LIN_description_file;
LIN_protocol_version = "J2602_1_2.0";
LIN_language_version = "J2602_3_2.0";
LDF_file_revision = "14.23.01";
LIN_speed = 10.417 kbps;

Nodes {
  Commander: CEM, 5 ms, 0.1 ms, 34 bit, 30 %;
  Responders: LSM ;
}

Signals {
  InternalLightsRequest: 2, 0, CEM, LSM ;
  LeftIntLightsSwitch: 8, 0, LSM, CEM ;
  LSMerror: 1, 0, LSM, CEM ;
  IntTest: 2, 0, LSM, CEM ;
  Character: 8, 0, CEM, LSM ;
  Digit: 4, 0, CEM, LSM ;
  Load: 32, {0, 0, 0, 0}, LSM, CEM ;
  LSM_Reset: 1, 0, LSM, CEM ;
  CEM_Frm2_NewSignal: 8, 0, CEM ;
}

Diagnostic_signals {
  CommanderReqB0: 8, 0 ;
  CommanderReqB1: 8, 0 ;
  CommanderReqB2: 8, 0 ;
  CommanderReqB3: 8, 0 ;
  CommanderReqB4: 8, 0 ;
  CommanderReqB5: 8, 0 ;
  CommanderReqB6: 8, 0 ;
  CommanderReqB7: 8, 0 ;
  ResponderRespB0: 8, 0 ;
  ResponderRespB1: 8, 0 ;
  ResponderRespB2: 8, 0 ;
  ResponderRespB3: 8, 0 ;
  ResponderRespB4: 8, 0 ;
  ResponderRespB5: 8, 0 ;
  ResponderRespB6: 8, 0 ;
  ResponderRespB7: 8, 0 ;
}

Frames {
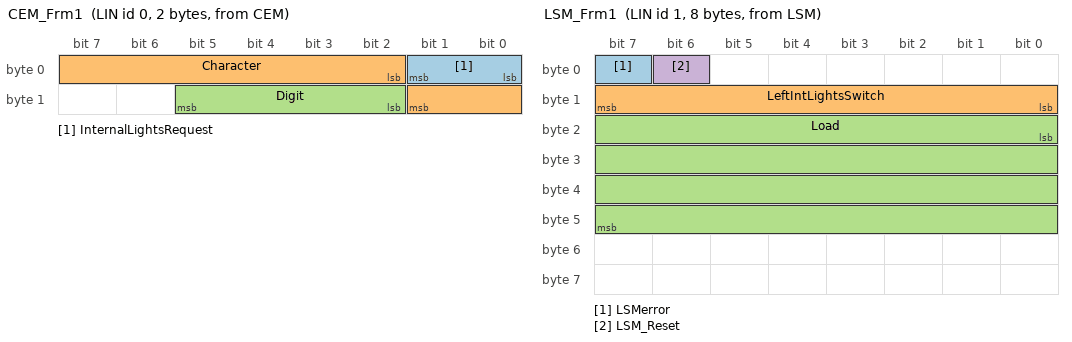
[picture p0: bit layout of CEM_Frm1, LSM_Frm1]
  CEM_Frm1: 0, CEM, 2 {
    InternalLightsRequest, 0 ;
    Character, 2 ;
    Digit, 10 ;
  }
  LSM_Frm1: 1, LSM, 8 {
    LSMerror, 7 ;
    LeftIntLightsSwitch, 8 ;
    Load, 16 ;
    LSM_Reset, 6 ;
  }
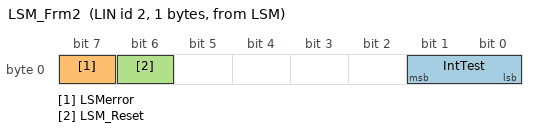
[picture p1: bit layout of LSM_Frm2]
  LSM_Frm2: 2, LSM, 1 {
    IntTest, 0 ;
    LSMerror, 7 ;
    LSM_Reset, 6 ;
  }
}

Diagnostic_frames {
  CommanderReq: 0x3c {
    CommanderReqB0, 0 ;
    CommanderReqB1, 8 ;
    CommanderReqB2, 16 ;
    CommanderReqB3, 24 ;
    CommanderReqB4, 32 ;
    CommanderReqB5, 40 ;
    CommanderReqB6, 48 ;
    CommanderReqB7, 56 ;
  }
  ResponderResp: 0x3d {
    ResponderRespB0, 0 ;
    ResponderRespB1, 8 ;
    ResponderRespB2, 16 ;
    ResponderRespB3, 24 ;
    ResponderRespB4, 32 ;
    ResponderRespB5, 40 ;
    ResponderRespB6, 48 ;
    ResponderRespB7, 56 ;
  }
}

Node_attributes {
  LSM{
    LIN_protocol = "J2602_1_2.0" ;
    configured_NAD = 0x60 ;
    initial_NAD = 0x60 ;
    product_id = 0x4A4F, 0x4841, 255 ;
    response_error = LSMerror ;
    fault_state_signals = IntTest ;
    P2_min = 10 ms ;
    ST_min = 0 ms ;
    N_As_timeout = 0 ms ;
    N_Cr_timeout = 0 ms ;
    response_tolerance = 30 % ;
    wakeup_time = 60 ms;
    poweron_time = 90 ms;
    configurable_frames {
      CEM_Frm1 ;
      LSM_Frm1 ;
      LSM_Frm2 ;
    }
  }
}

Schedule_tables {
 Normal_Schedule {
    LSM_Frm1 delay 20 ms ;
    CEM_Frm1 delay 30 ms ;
    LSM_Frm2 delay 30 ms ;
  }
 MRF_schedule {
    CommanderReq delay 20 ms ;
  }
 SRF_schedule {
    ResponderResp delay 20 ms ;
  }
}

Signal_encoding_types {
  ASCII_code {
    ascii_value ;
  }
  BCD_code {
    bcd_value ;
  }
  Dig2Bit {
    logical_value, 0, "off" ;
    logical_value, 1, "on" ;
    logical_value, 2, "error" ;
    logical_value, 3, "void" ;
  }
  ErrorEncoding {
    logical_value, 0, "OK" ;
    logical_value, 1, "error" ;
  }
  FaultStateEncoding {
    logical_value, 0, "No test result" ;
    logical_value, 1, "failed" ;
    logical_value, 2, "passed" ;
    logical_value, 3, "not used" ;
  }
  IEEE754_1985 {
    float_value ;
  }
  LightEncoding {
    physical_value, 1, 254, 1, 100, "lux" ;
    logical_value, 0, "Off" ;
    logical_value, 255, "error" ;
  }
}

Signal_representation {
  ASCII_code: Character ;
  BCD_code: Digit ;
  Dig2Bit: InternalLightsRequest ;
  ErrorEncoding: LSMerror ;
  FaultStateEncoding: IntTest ;
  IEEE754_1985: Load ;
  LightEncoding: LeftIntLightsSwitch ;
}
